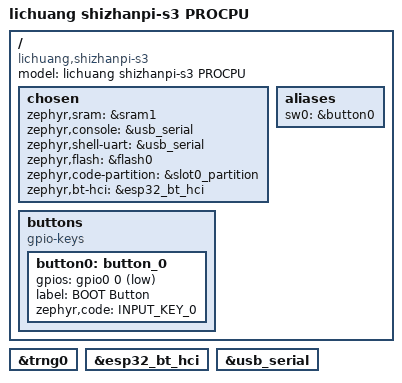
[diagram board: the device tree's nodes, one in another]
/*
 * Copyright (c) 2025 liangyq <liangyongqincn@gmail.com>
 *
 * SPDX-License-Identifier: Apache-2.0
 */
/dts-v1/;

#include <espressif/esp32s3/esp32s3_wroom_n16r8.dtsi>
#include <zephyr/dt-bindings/input/input-event-codes.h>
#include <zephyr/dt-bindings/input/esp32-touch-sensor-input.h>
#include <espressif/partitions_0x0_amp_16M.dtsi>
#include "shizhanpi_s3-pinctrl.dtsi"

/ {
	model = "lichuang shizhanpi-s3 PROCPU";
	compatible = "lichuang,shizhanpi-s3";

	chosen {
		zephyr,sram = &sram1;
		zephyr,console = &usb_serial;
		zephyr,shell-uart = &usb_serial;
		zephyr,flash = &flash0;
		zephyr,code-partition = &slot0_partition;
		zephyr,bt-hci = &esp32_bt_hci;
	};

	buttons: buttons {
		compatible = "gpio-keys";
		button0: button_0 {
			gpios = <&gpio0 0 (GPIO_PULL_UP | GPIO_ACTIVE_LOW)>;
			label = "BOOT Button";
			zephyr,code = <INPUT_KEY_0>;
		};
	};

	aliases {
		sw0 = &button0;
	};
};

&trng0 {
	status = "okay";
};

&esp32_bt_hci {
	status = "okay";
};

&usb_serial {
	status = "okay";
};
